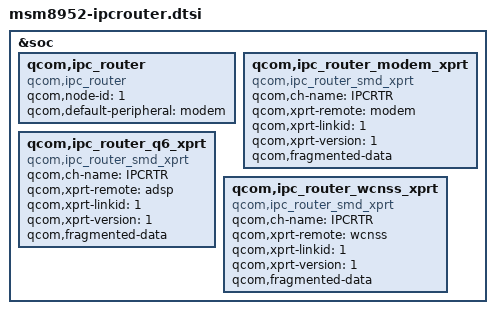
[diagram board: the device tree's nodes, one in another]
/* Copyright (c) 2014-2015, The Linux Foundation. All rights reserved.
 *
 * This program is free software; you can redistribute it and/or modify
 * it under the terms of the GNU General Public License version 2 and
 * only version 2 as published by the Free Software Foundation.
 *
 * This program is distributed in the hope that it will be useful,
 * but WITHOUT ANY WARRANTY; without even the implied warranty of
 * MERCHANTABILITY or FITNESS FOR A PARTICULAR PURPOSE.  See the
 * GNU General Public License for more details.
 */

&soc {
	qcom,ipc_router {
		compatible = "qcom,ipc_router";
		qcom,node-id = <1>;
		qcom,default-peripheral = "modem";
	};

	qcom,ipc_router_modem_xprt {
		compatible = "qcom,ipc_router_smd_xprt";
		qcom,ch-name = "IPCRTR";
		qcom,xprt-remote = "modem";
		qcom,xprt-linkid = <1>;
		qcom,xprt-version = <1>;
		qcom,fragmented-data;
	};

	qcom,ipc_router_q6_xprt {
		compatible = "qcom,ipc_router_smd_xprt";
		qcom,ch-name = "IPCRTR";
		qcom,xprt-remote = "adsp";
		qcom,xprt-linkid = <1>;
		qcom,xprt-version = <1>;
		qcom,fragmented-data;
	};

	qcom,ipc_router_wcnss_xprt {
		compatible = "qcom,ipc_router_smd_xprt";
		qcom,ch-name = "IPCRTR";
		qcom,xprt-remote = "wcnss";
		qcom,xprt-linkid = <1>;
		qcom,xprt-version = <1>;
		qcom,fragmented-data;
	};
};
